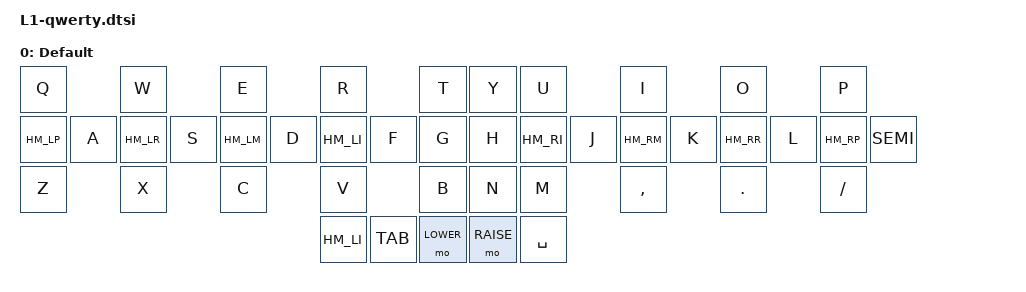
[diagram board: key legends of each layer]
/**
 *
 */

/ {
  keymap {
    compatible = "zmk,keymap";

	default_layer {
		label = "Default";
        bindings = <
//			╭───────────────┬───────────────┬───────────────┬───────────────┬───────────────╮   ╭───────────────┬───────────────┬───────────────┬───────────────┬───────────────╮
//  0               	1               2               3               4               5                   6               7               8               9               10
				&kp Q           &kp W           &kp E           &kp R           &kp T               &kp Y           &kp U           &kp I           &kp O           &kp P
		//	├───────────────┼───────────────┼───────────────┼───────────────┼───────────────┤   ├───────────────├───────────────┼───────────────┼───────────────┼───────────────┤
//  12					13              14              15              16              17                  18              19              20              21              22
				HM_LP A      	HM_LR S       	HM_LM D      	HM_LI F      	&kp G               &kp H           HM_RI J     	HM_RM K   		HM_RR L      	HM_RP SEMI
		//	├───────────────┼───────────────┼───────────────┼───────────────┼───────────────┤   ├───────────────├───────────────┼───────────────┼───────────────┼───────────────┤
//  24					25              26              27              28              29                  30              31              32              33              34
				&kp Z     		&kp X      		&kp C      		&kp V       	&kp B               &kp N           &kp M       	&kp COMMA  		&kp DOT   		&kp FSLH
		//	╰───────────────┴───────────────┼───────────────┼───────────────┼───────────────┤   ├───────────────├───────────────┼───────────────┼───────────────┴───────────────╯
//	36              													37              38                  39              40
	       														HM_LI TAB		&mo LOWER			&mo RAISE		&kp SPACE
//                                                          ╰───────────────┴───────────────╯   ╰───────────────┴───────────────╯

			>;

		};
    };
};
